# ATmega64HVE2 device description
Architecture: AVR8; Family: megaAVR
Registers are 8-bit, access not given, no defined reset value unless marked. A register's access mark holds for its fields unless they carry their own. Offsets are from the block's base; [hi:lo] are bit positions; {n}, {i} and the like mark numbered series.

## PORTB — I/O Port
Instances: PORTB 0x00
0x23 PINB — Port B Input Pins
0x24 DDRB — Port B Data Direction Register
0x25 PORTB — Port B Data Register
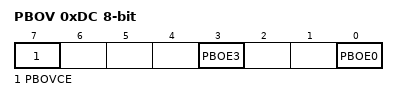
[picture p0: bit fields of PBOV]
0xDC PBOV — Port B Override
  [7] PBOVCE — Port B Override Change Enable
  [3] PBOE3 — Port B Override Enable 3
  [0] PBOE0 — Port B Override Enable 0

## PORTA — I/O Port
Instances: PORTA 0x00
0x20 PINA bits used 1:0 — Port A Input Pins
0x21 DDRA bits used 1:0 — Port A Data Direction Register
0x22 PORTA bits used 1:0 — Port A Data Register

## BOOT_LOAD — Bootloader
Instances: BOOT_LOAD 0x00
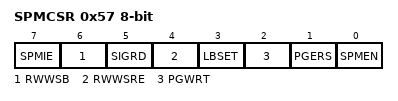
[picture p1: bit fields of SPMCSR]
0x57 SPMCSR — Store Program Memory Control and Status Register
  [7] SPMIE — SPM Interrupt Enable
  [6] RWWSB — Read-While-Write Section Busy
  [5] SIGRD — Signature Row Read
  [4] RWWSRE — Read-While-Write Section Read Enable
  [3] LBSET — Lock Bit Set
  [2] PGWRT — Page Write
  [1] PGERS — Page Erase
  [0] SPMEN — Store Program Memory Enable

## ADC — Analog-to-Digital Converter
Instances: ADC 0x00
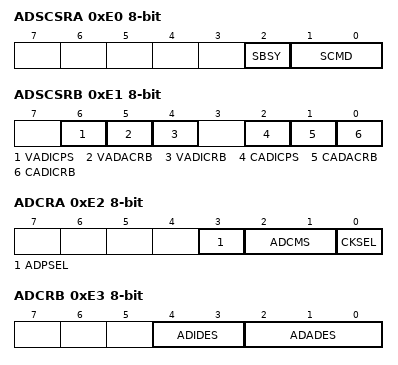
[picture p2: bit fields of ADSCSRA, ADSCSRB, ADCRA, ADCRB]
0xE0 ADSCSRA — ADC Synchronization Control and Status Register
  [2] SBSY — Synchronization Busy
  [1:0] SCMD — Synchronization Command
    1=Reset and Synchronize; 2=Synchronize on next Instantaneous Conversion; 3=Synchronize on next Accumulated Conversion
0xE1 ADSCSRB — ADC Synchronization Control and Status Register
  [6] VADICPS — V-ADC Instantaneous Conversion Polarity Status
  [5] VADACRB — VADAC Data Read Out Busy
  [4] VADICRB — VADIC Data Read Out Busy
  [2] CADICPS — C-ADC Instantaneous Conversion Polarity Status
  [1] CADACRB — CADAC Data Read Out Busy
  [0] CADICRB — CADIC Data Read Out Busy
0xE2 ADCRA — ADC Control Register A
  [3] ADPSEL — ADC Polarity Select
  [2:1] ADCMS — C-ADC Chopper Mode Select
    0=Chopping Disabled; 1=Automatic Fast Chopping; 2=Automatic Slow Chopping; 3=Software Polarity Control
  [0] CKSEL — Sampling Clock Select
    0=PLL (512kHz output) as sampling clock; 1=Slow RC Oscillator as sampling clock
0xE3 ADCRB — ADC Control Register B
  [4:3] ADIDES — Instantaneous Decimation Ratio Select
    0=512; 1=256; 2=128; 3=64
  [2:0] ADADES — Accumulated Decimation Ratio Select
    0=512; 1=256; 2=128; 3=64; 4=32; 5=16; 6=8; 7=4
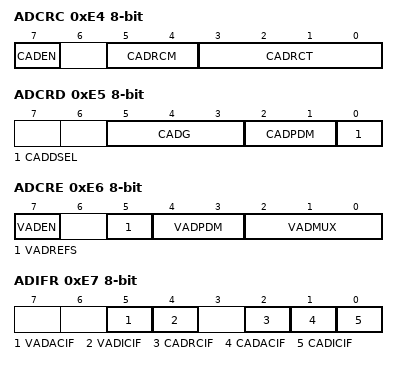
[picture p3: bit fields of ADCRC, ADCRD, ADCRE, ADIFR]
0xE4 ADCRC — ADC Control Register B
  [7] CADEN — C-ADC Enable
  [5:4] CADRCM — C-ADC Regular Current Comparator Mode
    0=Comparator Disabled; 1=Comparator Enabled. Regular Current Counter counts up if Accumulated Current is above threshold and is reset if Accumulated Current is below threshold.; 2=Comparator Enabled. Regular Current Counter counts up if Accumulated Current is above threshold and down if Accumulated Current is below threshold.
  [3:0] CADRCT — C-ADC Regular Current Count Threshold
    {v}={v+1} (v=0..15)
0xE5 ADCRD — ADC Control Register D
  [5:3] CADG — C-ADC Gain
    0=4x; 1=8x; 2=16x; 3=32x; 4=64x; 5=128x; 6=256x
  [2:1] CADPDM — C-ADC Pin Diagnostics Mode
    0=No current source is enabled; 1=Current source on PI pin enabled; 2=Current source on NI pin enabled; 3=Current source on both PI/NI pins enabled
  [0] CADDSEL — C-ADC Diagnostics Channel Select
0xE6 ADCRE — ADC Control Register E
  [7] VADEN — V-ADC Enable
  [5] VADREFS — V-ADC Reference Select
    0=VREF as reference; 1=AVDD/3 as reference (for diagnosis purpose)
  [4:3] VADPDM — V-ADC Pin Diagnostics Mode
    0=No current source is enabled; 1=Current source on PV pin enabled; 2=Current source on NV pin enabled; 3=Current source on both PV/NV pins enabled
  [2:0] VADMUX — V-ADC Channel Select
    0=PV - NV; 1=ADC0 - SGND; 2=ADC1 - SGND; 3=VTEMP - GND; 4=DIAGNOSIS - GND (VREF/TBD)
0xE7 ADIFR — ADC Interrupt Flag Register
  [5] VADACIF — V-ADC Accumulated Voltage Interrupt Flag
  [4] VADICIF — V-DAC Instantaneous Voltage Interrupt Flag
  [2] CADRCIF — C-ADC Regulator Current Interrupt Flag
  [1] CADACIF — C-ADC Accumulated Current Interrupt Flag
  [0] CADICIF — C-ADC Instantaneous Current Interrupt Flag
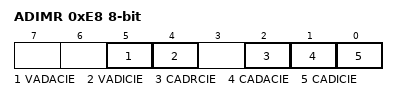
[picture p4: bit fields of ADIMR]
0xE8 ADIMR — ADC Interrupt Mask Register
  [5] VADACIE — V-ADC Accumulated Voltage Interrupt Enable
  [4] VADICIE — V-DAC Instantaneous Voltage Interrupt Enable
  [2] CADRCIE — C-ADC Regulator Current Interrupt Enable
  [1] CADACIE — C-ADC Accumulated Current Interrupt Enable
  [0] CADICIE — C-ADC Instantaneous Current Interrupt Enable
0xE9 CADRCL 16-bit — CC-ADC Regulator Current Comparator Threshold Level
0xEB CADIC 16-bit — C-ADC Instantaneous Conversion Result
{0xED+i} CADAC{i} (i=0..3) — C-ADC Accumulated Conversion Result
0xF1 VADIC 16-bit — V-ADC Instantaneous Conversion Result
{0xF3+i} VADAC{i} (i=0..3) — V-ADC Accumulated Conversion Result
